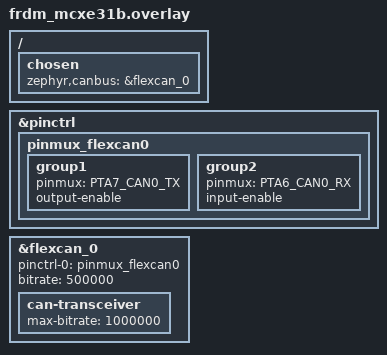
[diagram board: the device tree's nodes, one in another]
/*
 * Copyright 2025 NXP
 * SPDX-License-Identifier: Apache-2.0
 */

/ {
	chosen {
		zephyr,canbus = &flexcan_0;
	};
};

&pinctrl {
	pinmux_flexcan0: pinmux_flexcan0 {
		group1 {
			pinmux = <PTA7_CAN0_TX>;
			output-enable;
		};
		group2 {
			pinmux = <PTA6_CAN0_RX>;
			input-enable;
		};
	};
};

&flexcan_0 {
	status = "okay";
	pinctrl-0 = <&pinmux_flexcan0>;
	pinctrl-names = "default";
	bitrate = <500000>;

	can-transceiver {
		max-bitrate = <1000000>;
	};
};
